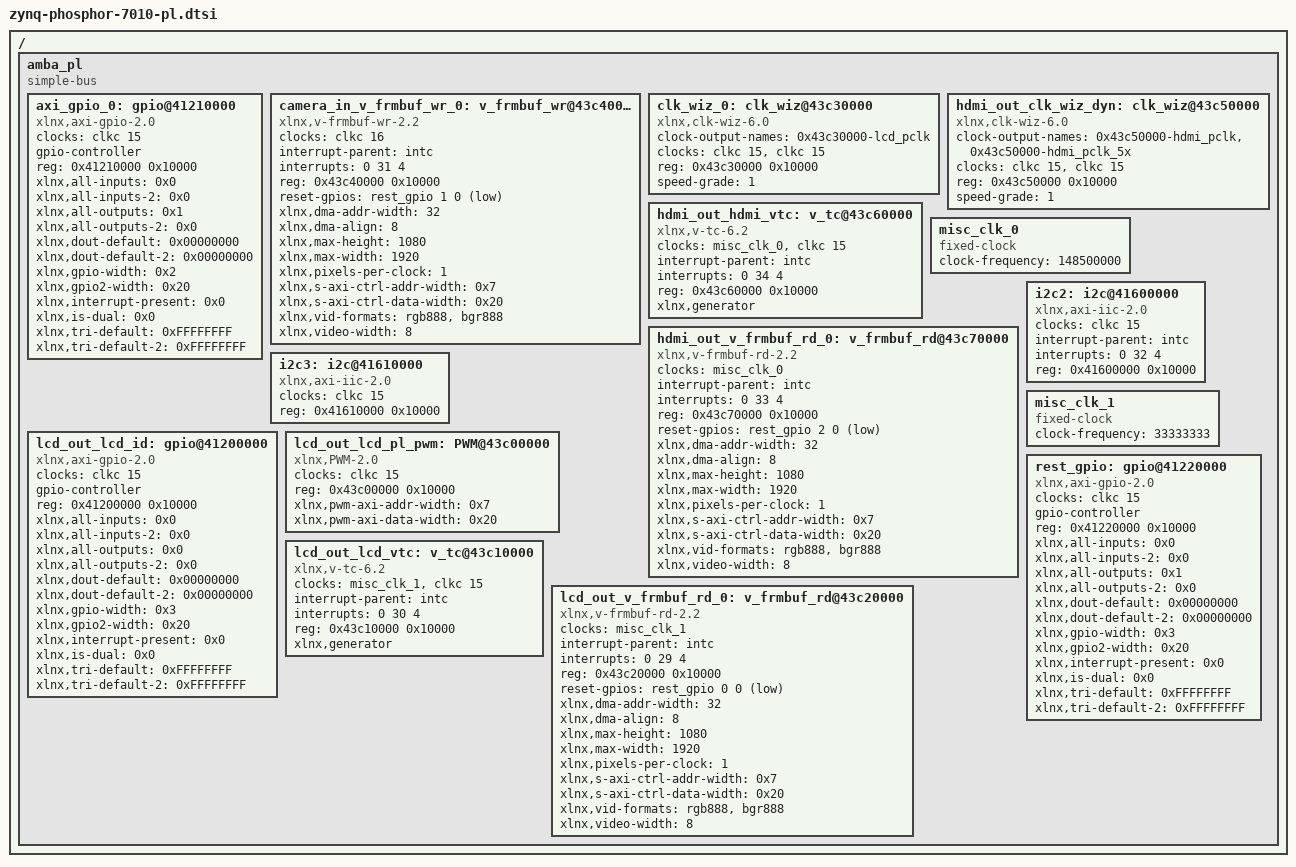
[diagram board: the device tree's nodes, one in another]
/*
 * CAUTION: This file is automatically generated by Xilinx.
 * Version:  
 * Today is: Tue Mar 18 09:25:12 2025
 */


/ {
	amba_pl: amba_pl {
		#address-cells = <1>;
		#size-cells = <1>;
		compatible = "simple-bus";
		ranges ;
		axi_gpio_0: gpio@41210000 {
			#gpio-cells = <3>;
			clock-names = "s_axi_aclk";
			clocks = <&clkc 15>;
			compatible = "xlnx,axi-gpio-2.0", "xlnx,xps-gpio-1.00.a";
			gpio-controller ;
			reg = <0x41210000 0x10000>;
			xlnx,all-inputs = <0x0>;
			xlnx,all-inputs-2 = <0x0>;
			xlnx,all-outputs = <0x1>;
			xlnx,all-outputs-2 = <0x0>;
			xlnx,dout-default = <0x00000000>;
			xlnx,dout-default-2 = <0x00000000>;
			xlnx,gpio-width = <0x2>;
			xlnx,gpio2-width = <0x20>;
			xlnx,interrupt-present = <0x0>;
			xlnx,is-dual = <0x0>;
			xlnx,tri-default = <0xFFFFFFFF>;
			xlnx,tri-default-2 = <0xFFFFFFFF>;
		};
		camera_in_v_frmbuf_wr_0: v_frmbuf_wr@43c40000 {
			#dma-cells = <1>;
			clock-names = "ap_clk";
			clocks = <&clkc 16>;
			compatible = "xlnx,v-frmbuf-wr-2.2", "xlnx,axi-frmbuf-wr-v2.1";
			interrupt-names = "interrupt";
			interrupt-parent = <&intc>;
			interrupts = <0 31 4>;
			reg = <0x43c40000 0x10000>;
			reset-gpios = <&rest_gpio 1 0 1>;
			xlnx,dma-addr-width = <32>;
			xlnx,dma-align = <8>;
			xlnx,max-height = <1080>;
			xlnx,max-width = <1920>;
			xlnx,pixels-per-clock = <1>;
			xlnx,s-axi-ctrl-addr-width = <0x7>;
			xlnx,s-axi-ctrl-data-width = <0x20>;
			xlnx,vid-formats = "rgb888", "bgr888";
			xlnx,video-width = <8>;
		};
		clk_wiz_0: clk_wiz@43c30000 {
			#clock-cells = <1>;
			clock-names = "s_axi_aclk", "clk_in1";
			clock-output-names = "0x43c30000-lcd_pclk";
			clocks = <&clkc 15>, <&clkc 15>;
			compatible = "xlnx,clk-wiz-6.0", "xlnx,clocking-wizard";
			reg = <0x43c30000 0x10000>;
			speed-grade = <1>;
		};
		hdmi_out_clk_wiz_dyn: clk_wiz@43c50000 {
			#clock-cells = <1>;
			clock-names = "s_axi_aclk", "clk_in1";
			clock-output-names = "0x43c50000-hdmi_pclk", "0x43c50000-hdmi_pclk_5x";
			clocks = <&clkc 15>, <&clkc 15>;
			compatible = "xlnx,clk-wiz-6.0", "xlnx,clocking-wizard";
			reg = <0x43c50000 0x10000>;
			speed-grade = <1>;
		};
		hdmi_out_hdmi_vtc: v_tc@43c60000 {
			clock-names = "clk", "s_axi_aclk";
			clocks = <&misc_clk_0>, <&clkc 15>;
			compatible = "xlnx,v-tc-6.2", "xlnx,v-tc-6.1";
			interrupt-names = "irq";
			interrupt-parent = <&intc>;
			interrupts = <0 34 4>;
			reg = <0x43c60000 0x10000>;
			xlnx,generator ;
		};
		misc_clk_0: misc_clk_0 {
			#clock-cells = <0>;
			clock-frequency = <148500000>;
			compatible = "fixed-clock";
		};
		hdmi_out_v_frmbuf_rd_0: v_frmbuf_rd@43c70000 {
			#dma-cells = <1>;
			clock-names = "ap_clk";
			clocks = <&misc_clk_0>;
			compatible = "xlnx,v-frmbuf-rd-2.2", "xlnx,axi-frmbuf-rd-v2.1";
			interrupt-names = "interrupt";
			interrupt-parent = <&intc>;
			interrupts = <0 33 4>;
			reg = <0x43c70000 0x10000>;
			reset-gpios = <&rest_gpio 2 0 1>;
			xlnx,dma-addr-width = <32>;
			xlnx,dma-align = <8>;
			xlnx,max-height = <1080>;
			xlnx,max-width = <1920>;
			xlnx,pixels-per-clock = <1>;
			xlnx,s-axi-ctrl-addr-width = <0x7>;
			xlnx,s-axi-ctrl-data-width = <0x20>;
			xlnx,vid-formats = "rgb888", "bgr888";
			xlnx,video-width = <8>;
		};
		i2c2: i2c@41600000 {
			#address-cells = <1>;
			#size-cells = <0>;
			clock-names = "s_axi_aclk";
			clocks = <&clkc 15>;
			compatible = "xlnx,axi-iic-2.0", "xlnx,xps-iic-2.00.a";
			interrupt-names = "iic2intc_irpt";
			interrupt-parent = <&intc>;
			interrupts = <0 32 4>;
			reg = <0x41600000 0x10000>;
		};
		i2c3: i2c@41610000 {
			#address-cells = <1>;
			#size-cells = <0>;
			clock-names = "s_axi_aclk";
			clocks = <&clkc 15>;
			compatible = "xlnx,axi-iic-2.0", "xlnx,xps-iic-2.00.a";
			reg = <0x41610000 0x10000>;
		};
		lcd_out_lcd_id: gpio@41200000 {
			#gpio-cells = <3>;
			clock-names = "s_axi_aclk";
			clocks = <&clkc 15>;
			compatible = "xlnx,axi-gpio-2.0", "xlnx,xps-gpio-1.00.a";
			gpio-controller ;
			reg = <0x41200000 0x10000>;
			xlnx,all-inputs = <0x0>;
			xlnx,all-inputs-2 = <0x0>;
			xlnx,all-outputs = <0x0>;
			xlnx,all-outputs-2 = <0x0>;
			xlnx,dout-default = <0x00000000>;
			xlnx,dout-default-2 = <0x00000000>;
			xlnx,gpio-width = <0x3>;
			xlnx,gpio2-width = <0x20>;
			xlnx,interrupt-present = <0x0>;
			xlnx,is-dual = <0x0>;
			xlnx,tri-default = <0xFFFFFFFF>;
			xlnx,tri-default-2 = <0xFFFFFFFF>;
		};
		lcd_out_lcd_pl_pwm: PWM@43c00000 {
			clock-names = "pwm_axi_aclk";
			clocks = <&clkc 15>;
			compatible = "xlnx,PWM-2.0";
			reg = <0x43c00000 0x10000>;
			xlnx,pwm-axi-addr-width = <0x7>;
			xlnx,pwm-axi-data-width = <0x20>;
		};
		lcd_out_lcd_vtc: v_tc@43c10000 {
			clock-names = "clk", "s_axi_aclk";
			clocks = <&misc_clk_1>, <&clkc 15>;
			compatible = "xlnx,v-tc-6.2", "xlnx,v-tc-6.1";
			interrupt-names = "irq";
			interrupt-parent = <&intc>;
			interrupts = <0 30 4>;
			reg = <0x43c10000 0x10000>;
			xlnx,generator ;
		};
		misc_clk_1: misc_clk_1 {
			#clock-cells = <0>;
			clock-frequency = <33333333>;
			compatible = "fixed-clock";
		};
		lcd_out_v_frmbuf_rd_0: v_frmbuf_rd@43c20000 {
			#dma-cells = <1>;
			clock-names = "ap_clk";
			clocks = <&misc_clk_1>;
			compatible = "xlnx,v-frmbuf-rd-2.2", "xlnx,axi-frmbuf-rd-v2.1";
			interrupt-names = "interrupt";
			interrupt-parent = <&intc>;
			interrupts = <0 29 4>;
			reg = <0x43c20000 0x10000>;
			reset-gpios = <&rest_gpio 0 0 1>;
			xlnx,dma-addr-width = <32>;
			xlnx,dma-align = <8>;
			xlnx,max-height = <1080>;
			xlnx,max-width = <1920>;
			xlnx,pixels-per-clock = <1>;
			xlnx,s-axi-ctrl-addr-width = <0x7>;
			xlnx,s-axi-ctrl-data-width = <0x20>;
			xlnx,vid-formats = "rgb888", "bgr888";
			xlnx,video-width = <8>;
		};
		rest_gpio: gpio@41220000 {
			#gpio-cells = <3>;
			clock-names = "s_axi_aclk";
			clocks = <&clkc 15>;
			compatible = "xlnx,axi-gpio-2.0", "xlnx,xps-gpio-1.00.a";
			gpio-controller ;
			reg = <0x41220000 0x10000>;
			xlnx,all-inputs = <0x0>;
			xlnx,all-inputs-2 = <0x0>;
			xlnx,all-outputs = <0x1>;
			xlnx,all-outputs-2 = <0x0>;
			xlnx,dout-default = <0x00000000>;
			xlnx,dout-default-2 = <0x00000000>;
			xlnx,gpio-width = <0x3>;
			xlnx,gpio2-width = <0x20>;
			xlnx,interrupt-present = <0x0>;
			xlnx,is-dual = <0x0>;
			xlnx,tri-default = <0xFFFFFFFF>;
			xlnx,tri-default-2 = <0xFFFFFFFF>;
		};
	};
};
